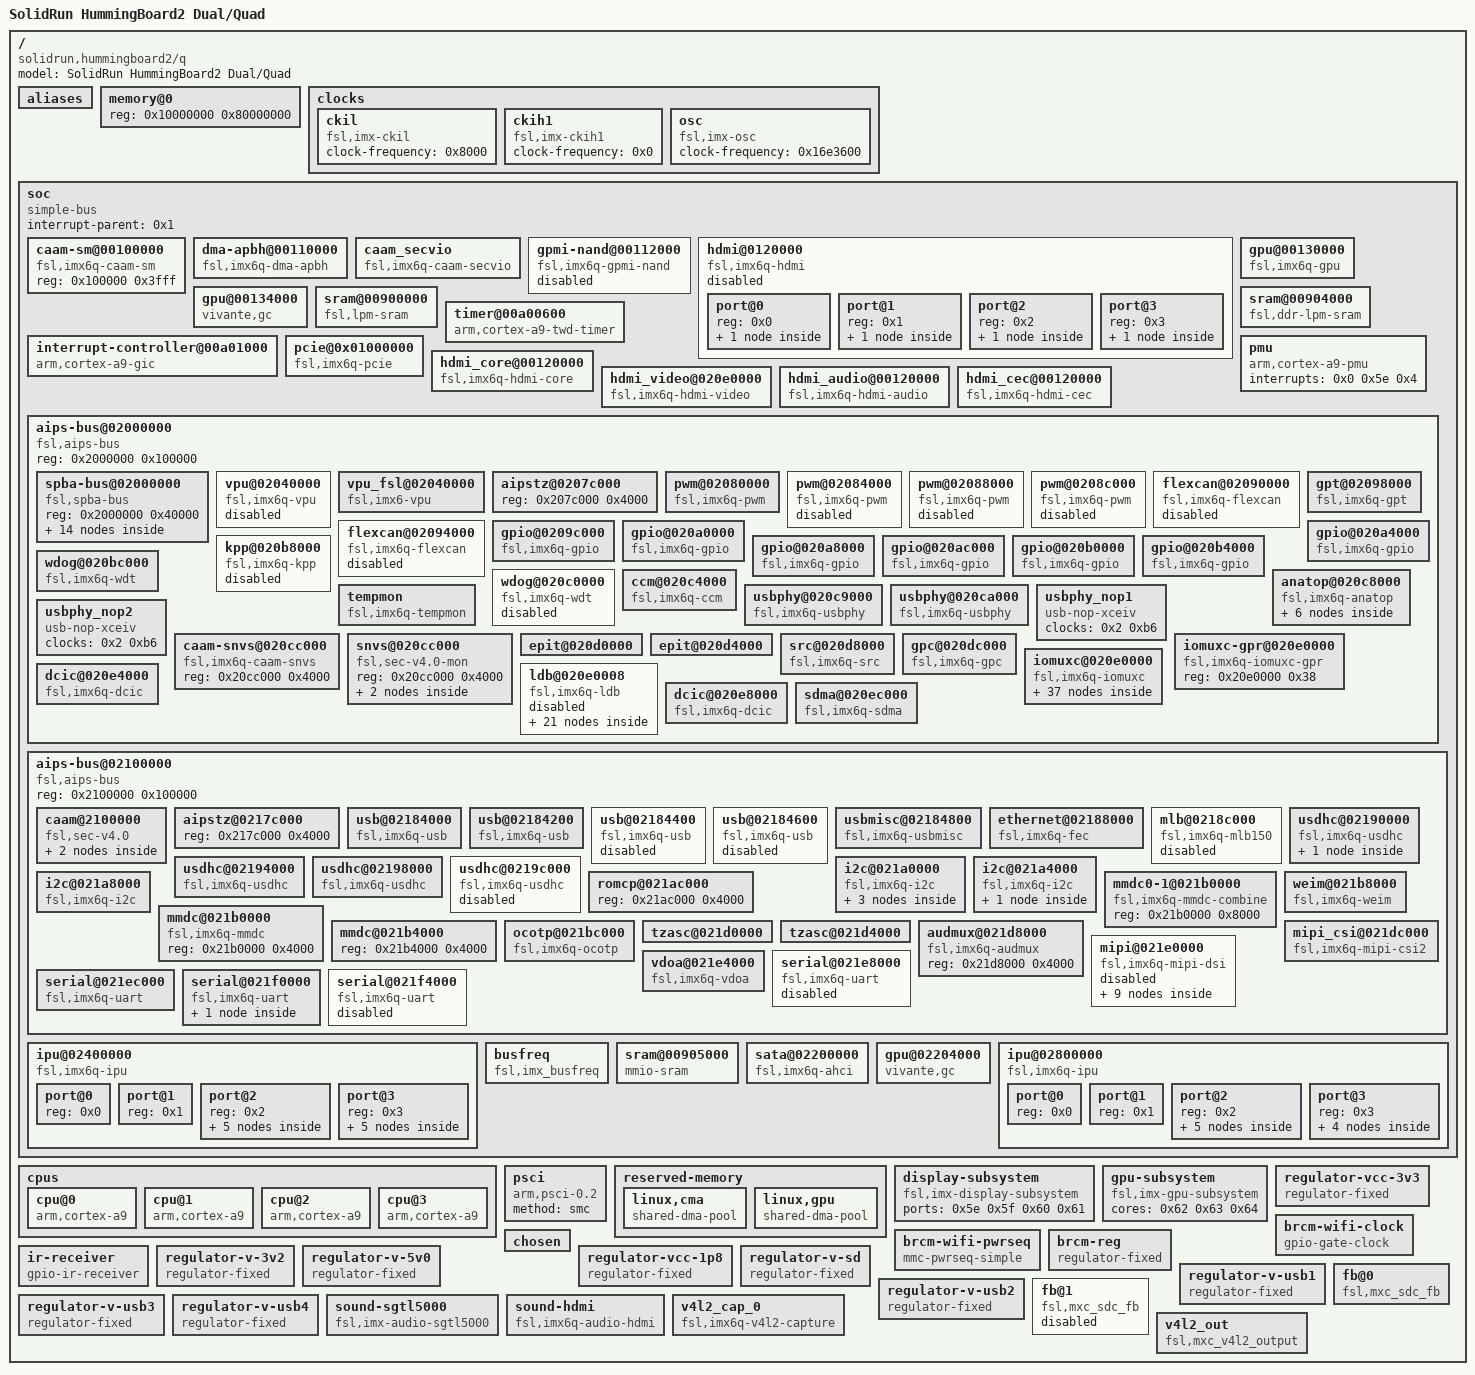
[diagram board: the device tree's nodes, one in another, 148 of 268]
/** @file
 * Copyright (c) 2017, Linaro Limited. All rights reserved.
 *
 * This program and the accompanying materials are licensed and made
 * available under the terms and conditions of the BSD License which
 * accompanies this distribution.  The full text of the license may be
 * found at http://opensource.org/licenses/bsd-license.php
 *
 * THE PROGRAM IS DISTRIBUTED UNDER THE BSD LICENSE ON AN "AS IS" BASIS,
 * WITHOUT WARRANTIES OR REPRESENTATIONS OF ANY KIND, EITHER EXPRESS OR
 * IMPLIED.
 */

/dts-v1/;

/ {
	#address-cells = <0x1>;
	#size-cells = <0x1>;
	model = "SolidRun HummingBoard2 Dual/Quad";
	compatible = "solidrun,hummingboard2/q", "fsl,imx6q";

	aliases {
		ethernet0 = "/soc/aips-bus@02100000/ethernet@02188000";
		can0 = "/soc/aips-bus@02000000/flexcan@02090000";
		can1 = "/soc/aips-bus@02000000/flexcan@02094000";
		gpio0 = "/soc/aips-bus@02000000/gpio@0209c000";
		gpio1 = "/soc/aips-bus@02000000/gpio@020a0000";
		gpio2 = "/soc/aips-bus@02000000/gpio@020a4000";
		gpio3 = "/soc/aips-bus@02000000/gpio@020a8000";
		gpio4 = "/soc/aips-bus@02000000/gpio@020ac000";
		gpio5 = "/soc/aips-bus@02000000/gpio@020b0000";
		gpio6 = "/soc/aips-bus@02000000/gpio@020b4000";
		i2c0 = "/soc/aips-bus@02100000/i2c@021a0000";
		i2c1 = "/soc/aips-bus@02100000/i2c@021a4000";
		i2c2 = "/soc/aips-bus@02100000/i2c@021a8000";
		ipu0 = "/soc/ipu@02400000";
		mmc0 = "/soc/aips-bus@02100000/usdhc@02194000";
		mmc1 = "/soc/aips-bus@02100000/usdhc@02190000";
		mmc2 = "/soc/aips-bus@02100000/usdhc@02198000";
		mmc3 = "/soc/aips-bus@02100000/usdhc@0219c000";
		serial0 = "/soc/aips-bus@02000000/spba-bus@02000000/serial@02020000";
		serial1 = "/soc/aips-bus@02100000/serial@021e8000";
		serial2 = "/soc/aips-bus@02100000/serial@021ec000";
		serial3 = "/soc/aips-bus@02100000/serial@021f0000";
		serial4 = "/soc/aips-bus@02100000/serial@021f4000";
		spi0 = "/soc/aips-bus@02000000/spba-bus@02000000/ecspi@02008000";
		spi1 = "/soc/aips-bus@02000000/spba-bus@02000000/ecspi@0200c000";
		spi2 = "/soc/aips-bus@02000000/spba-bus@02000000/ecspi@02010000";
		spi3 = "/soc/aips-bus@02000000/spba-bus@02000000/ecspi@02014000";
		usbphy0 = "/soc/aips-bus@02000000/usbphy@020c9000";
		usbphy1 = "/soc/aips-bus@02000000/usbphy@020ca000";
		ipu1 = "/soc/ipu@02800000";
		spi4 = "/soc/aips-bus@02000000/spba-bus@02000000/ecspi@02018000";
		mxcfb0 = "/fb@0";
		mxcfb2 = "/fb@1";
	};

	memory@0 {
		device_type = "memory";
		reg = <0x10000000 0x80000000>;
	};

	clocks {
		#address-cells = <0x1>;
		#size-cells = <0x0>;

		ckil {
			compatible = "fsl,imx-ckil", "fixed-clock";
			#clock-cells = <0x0>;
			clock-frequency = <0x8000>;
		};

		ckih1 {
			compatible = "fsl,imx-ckih1", "fixed-clock";
			#clock-cells = <0x0>;
			clock-frequency = <0x0>;
		};

		osc {
			compatible = "fsl,imx-osc", "fixed-clock";
			#clock-cells = <0x0>;
			clock-frequency = <0x16e3600>;
		};
	};

	soc {
		#address-cells = <0x1>;
		#size-cells = <0x1>;
		compatible = "simple-bus";
		interrupt-parent = <0x1>;
		ranges;

		caam-sm@00100000 {
			compatible = "fsl,imx6q-caam-sm";
			reg = <0x100000 0x3fff>;
		};

		dma-apbh@00110000 {
			compatible = "fsl,imx6q-dma-apbh", "fsl,imx28-dma-apbh";
			reg = <0x110000 0x2000>;
			interrupts = <0x0 0xd 0x4 0x0 0xd 0x4 0x0 0xd 0x4 0x0 0xd 0x4>;
			interrupt-names = "gpmi0", "gpmi1", "gpmi2", "gpmi3";
			#dma-cells = <0x1>;
			dma-channels = <0x4>;
			clocks = <0x2 0x6a>;
			linux,phandle = <0x3>;
			phandle = <0x3>;
		};

		caam_secvio {
			compatible = "fsl,imx6q-caam-secvio";
			interrupts = <0x0 0x14 0x4>;
			secvio_src = <0x8000001d>;
			jtag-tamper = "disabled";
			watchdog-tamper = "enabled";
			internal-boot-tamper = "enabled";
			external-pin-tamper = "disabled";
		};

		gpmi-nand@00112000 {
			compatible = "fsl,imx6q-gpmi-nand";
			#address-cells = <0x1>;
			#size-cells = <0x1>;
			reg = <0x112000 0x2000 0x114000 0x2000>;
			reg-names = "gpmi-nand", "bch";
			interrupts = <0x0 0xf 0x4>;
			interrupt-names = "bch";
			clocks = <0x2 0x98 0x2 0x99 0x2 0x97 0x2 0x96 0x2 0x95>;
			clock-names = "gpmi_io", "gpmi_apb", "gpmi_bch", "gpmi_bch_apb", "per1_bch";
			dmas = <0x3 0x0>;
			dma-names = "rx-tx";
			status = "disabled";
		};

		hdmi@0120000 {
			#address-cells = <0x1>;
			#size-cells = <0x0>;
			reg = <0x120000 0x9000>;
			interrupts = <0x0 0x73 0x4>;
			gpr = <0x4>;
			clocks = <0x2 0x7b 0x2 0x7c>;
			clock-names = "iahb", "isfr";
			status = "disabled";
			compatible = "fsl,imx6q-hdmi";
			pinctrl-names = "default";
			pinctrl-0 = <0x5>;
			ddc-i2c-bus = <0x6>;

			port@0 {
				reg = <0x0>;

				endpoint {
					remote-endpoint = <0x7>;
					linux,phandle = <0x4b>;
					phandle = <0x4b>;
				};
			};

			port@1 {
				reg = <0x1>;

				endpoint {
					remote-endpoint = <0x8>;
					linux,phandle = <0x4f>;
					phandle = <0x4f>;
				};
			};

			port@2 {
				reg = <0x2>;

				endpoint {
					remote-endpoint = <0x9>;
					linux,phandle = <0x53>;
					phandle = <0x53>;
				};
			};

			port@3 {
				reg = <0x3>;

				endpoint {
					remote-endpoint = <0xa>;
					linux,phandle = <0x57>;
					phandle = <0x57>;
				};
			};
		};

		gpu@00130000 {
			compatible = "fsl,imx6q-gpu";
			reg = <0x130000 0x4000 0x134000 0x4000 0x2204000 0x4000 0x10000000 0x0 0x0 0x8000000>;
			interrupts = <0x0 0x9 0x4 0x0 0xa 0x4 0x0 0xb 0x4>;
			clocks = <0x2 0x1a 0x2 0x8f 0x2 0x1b 0x2 0x79 0x2 0x7a 0x2 0x4a>;
			clock-names = "gpu2d_axi_clk", "openvg_axi_clk", "gpu3d_axi_clk", "gpu2d_clk", "gpu3d_clk", "gpu3d_shader_clk";
			power-domains = <0x1 0x1>;
			reg-names = "iobase_3d", "iobase_2d", "iobase_vg", "phys_baseaddr", "contiguous_mem";
			interrupt-names = "irq_3d", "irq_2d", "irq_vg";
			resets = <0xb 0x0 0xb 0x3 0xb 0x3>;
			reset-names = "gpu3d", "gpu2d", "gpuvg";
			memory-region = <0xc>;
			linux,phandle = <0x63>;
			phandle = <0x63>;
		};

		gpu@00134000 {
			compatible = "vivante,gc";
			reg = <0x134000 0x4000>;
			interrupts = <0x0 0xa 0x4>;
			clocks = <0x2 0x1a 0x2 0x79>;
			clock-names = "bus", "core";
			power-domains = <0x1 0x1>;
			memory-region = <0xc>;
			linux,phandle = <0x62>;
			phandle = <0x62>;
		};

		sram@00900000 {
			compatible = "fsl,lpm-sram";
			reg = <0x900000 0x4000>;
			clocks = <0x2 0x8e>;
		};

		sram@00904000 {
			compatible = "fsl,ddr-lpm-sram";
			reg = <0x904000 0x1000>;
			clocks = <0x2 0x8e>;
		};

		timer@00a00600 {
			compatible = "arm,cortex-a9-twd-timer";
			reg = <0xa00600 0x20>;
			interrupts = <0x1 0xd 0xf01>;
			interrupt-parent = <0xd>;
			clocks = <0x2 0xf>;
		};

		interrupt-controller@00a01000 {
			compatible = "arm,cortex-a9-gic";
			#interrupt-cells = <0x3>;
			interrupt-controller;
			reg = <0xa01000 0x1000 0xa00100 0x100>;
			interrupt-parent = <0xd>;
			linux,phandle = <0xd>;
			phandle = <0xd>;
		};

		pcie@0x01000000 {
			compatible = "fsl,imx6q-pcie", "snps,dw-pcie";
			reg = <0x1ffc000 0x4000 0x1f00000 0x80000>;
			reg-names = "dbi", "config";
			#address-cells = <0x3>;
			#size-cells = <0x2>;
			device_type = "pci";
			ranges = <0x81000000 0x0 0x0 0x1f80000 0x0 0x10000 0x82000000 0x0 0x1000000 0x1000000 0x0 0xf00000>;
			num-lanes = <0x1>;
			interrupts = <0x0 0x78 0x4>;
			interrupt-names = "msi";
			#interrupt-cells = <0x1>;
			interrupt-map-mask = <0x0 0x0 0x0 0x7>;
			interrupt-map = <0x0 0x0 0x0 0x1 0x1 0x0 0x7b 0x4 0x0 0x0 0x0 0x2 0x1 0x0 0x7a 0x4 0x0 0x0 0x0 0x3 0x1 0x0 0x79 0x4 0x0 0x0 0x0 0x4 0x1 0x0 0x78 0x4>;
			clocks = <0x2 0x90 0x2 0xce 0x2 0xbd>;
			clock-names = "pcie", "pcie_bus", "pcie_phy";
			fsl,max-link-speed = <0x2>;
			status = "okay";
			pinctrl-names = "default";
			pinctrl-0 = <0xe>;
			reset-gpio = <0xf 0xb 0x1>;
		};

		pmu {
			compatible = "arm,cortex-a9-pmu";
			interrupts = <0x0 0x5e 0x4>;
		};

		hdmi_core@00120000 {
			compatible = "fsl,imx6q-hdmi-core";
			reg = <0x120000 0x9000>;
			clocks = <0x2 0x7c 0x2 0x7b 0x2 0x8a>;
			clock-names = "hdmi_isfr", "hdmi_iahb", "mipi_core";
			status = "okay";
			ipu_id = <0x0>;
			disp_id = <0x0>;
		};

		hdmi_video@020e0000 {
			compatible = "fsl,imx6q-hdmi-video";
			reg = <0x20e0000 0x1000>;
			reg-names = "hdmi_gpr";
			interrupts = <0x0 0x73 0x4>;
			clocks = <0x2 0x7c 0x2 0x7b 0x2 0x8a>;
			clock-names = "hdmi_isfr", "hdmi_iahb", "mipi_core";
			status = "okay";
			fsl,phy_reg_vlev = <0x294>;
			fsl,phy_reg_cksymtx = <0x800d>;
		};

		hdmi_audio@00120000 {
			compatible = "fsl,imx6q-hdmi-audio";
			clocks = <0x2 0x7c 0x2 0x7b 0x2 0x8a>;
			clock-names = "hdmi_isfr", "hdmi_iahb", "mipi_core";
			dmas = <0x10 0x2 0x19 0x0>;
			dma-names = "tx";
			status = "okay";
			linux,phandle = <0x75>;
			phandle = <0x75>;
		};

		hdmi_cec@00120000 {
			compatible = "fsl,imx6q-hdmi-cec";
			interrupts = <0x0 0x73 0x4>;
			status = "okay";
			pinctrl-names = "default";
			pinctrl-0 = <0x5>;
		};

		aips-bus@02000000 {
			compatible = "fsl,aips-bus", "simple-bus";
			#address-cells = <0x1>;
			#size-cells = <0x1>;
			reg = <0x2000000 0x100000>;
			ranges;

			spba-bus@02000000 {
				compatible = "fsl,spba-bus", "simple-bus";
				#address-cells = <0x1>;
				#size-cells = <0x1>;
				reg = <0x2000000 0x40000>;
				ranges;

				spdif@02004000 {
					compatible = "fsl,imx35-spdif";
					reg = <0x2004000 0x4000>;
					interrupts = <0x0 0x34 0x4>;
					dmas = <0x10 0xe 0x12 0x0 0x10 0xf 0x12 0x0>;
					dma-names = "rx", "tx";
					clocks = <0x2 0xf4 0x2 0x3 0x2 0xc5 0x2 0x0 0x2 0x0 0x2 0x0 0x2 0x3e 0x2 0x0 0x2 0x0 0x2 0x9c>;
					clock-names = "core", "rxtx0", "rxtx1", "rxtx2", "rxtx3", "rxtx4", "rxtx5", "rxtx6", "rxtx7", "spba";
					status = "disabled";
				};

				ecspi@02008000 {
					#address-cells = <0x1>;
					#size-cells = <0x0>;
					compatible = "fsl,imx6q-ecspi", "fsl,imx51-ecspi";
					reg = <0x2008000 0x4000>;
					interrupts = <0x0 0x1f 0x4>;
					clocks = <0x2 0x70 0x2 0x70>;
					clock-names = "ipg", "per";
					dmas = <0x10 0x3 0x7 0x1 0x10 0x4 0x7 0x2>;
					dma-names = "rx", "tx";
					status = "disabled";
				};

				ecspi@0200c000 {
					#address-cells = <0x1>;
					#size-cells = <0x0>;
					compatible = "fsl,imx6q-ecspi", "fsl,imx51-ecspi";
					reg = <0x200c000 0x4000>;
					interrupts = <0x0 0x20 0x4>;
					clocks = <0x2 0x71 0x2 0x71>;
					clock-names = "ipg", "per";
					dmas = <0x10 0x5 0x7 0x1 0x10 0x6 0x7 0x2>;
					dma-names = "rx", "tx";
					status = "okay";
					pinctrl-names = "default";
					pinctrl-0 = <0x11>;
					cs-gpios = <0xf 0x1a 0x0>;
					fsl,spi-num-chipselects = <0x1>;

					spi@0 {
						compatible = "spidev";
						reg = <0x0>;
						spi-max-frequency = <0x1312d00>;
					};
				};

				ecspi@02010000 {
					#address-cells = <0x1>;
					#size-cells = <0x0>;
					compatible = "fsl,imx6q-ecspi", "fsl,imx51-ecspi";
					reg = <0x2010000 0x4000>;
					interrupts = <0x0 0x21 0x4>;
					clocks = <0x2 0x72 0x2 0x72>;
					clock-names = "ipg", "per";
					dmas = <0x10 0x7 0x7 0x1 0x10 0x8 0x7 0x2>;
					dma-names = "rx", "tx";
					status = "disabled";
				};

				ecspi@02014000 {
					#address-cells = <0x1>;
					#size-cells = <0x0>;
					compatible = "fsl,imx6q-ecspi", "fsl,imx51-ecspi";
					reg = <0x2014000 0x4000>;
					interrupts = <0x0 0x22 0x4>;
					clocks = <0x2 0x73 0x2 0x73>;
					clock-names = "ipg", "per";
					dmas = <0x10 0x9 0x7 0x1 0x10 0xa 0x7 0x2>;
					dma-names = "rx", "tx";
					status = "disabled";
				};

				serial@02020000 {
					compatible = "fsl,imx6q-uart", "fsl,imx21-uart";
					reg = <0x2020000 0x4000>;
					interrupts = <0x0 0x1a 0x4>;
					clocks = <0x2 0xa0 0x2 0xa1>;
					clock-names = "ipg", "per";
					dmas = <0x10 0x19 0x4 0x0 0x10 0x1a 0x4 0x0>;
					dma-names = "rx", "tx";
					status = "okay";
					pinctrl-names = "default";
					pinctrl-0 = <0x12>;
				};

				esai@02024000 {
					#sound-dai-cells = <0x0>;
					compatible = "fsl,imx35-esai";
					reg = <0x2024000 0x4000>;
					interrupts = <0x0 0x33 0x4>;
					clocks = <0x2 0xd0 0x2 0xd1 0x2 0x76 0x2 0xd0 0x2 0x9c>;
					clock-names = "core", "mem", "extal", "fsys", "spba";
					dmas = <0x10 0x17 0x15 0x0 0x10 0x18 0x15 0x0>;
					dma-names = "rx", "tx";
					status = "disabled";
				};

				ssi@02028000 {
					#sound-dai-cells = <0x0>;
					compatible = "fsl,imx6q-ssi", "fsl,imx51-ssi";
					reg = <0x2028000 0x4000>;
					interrupts = <0x0 0x2e 0x4>;
					clocks = <0x2 0xb2 0x2 0x9d>;
					clock-names = "ipg", "baud";
					dmas = <0x10 0x25 0x16 0x0 0x10 0x26 0x16 0x0>;
					dma-names = "rx", "tx";
					fsl,fifo-depth = <0xf>;
					status = "okay";
					fsl,mode = "i2s-slave";
					linux,phandle = <0x74>;
					phandle = <0x74>;
				};

				ssi@0202c000 {
					#sound-dai-cells = <0x0>;
					compatible = "fsl,imx6q-ssi", "fsl,imx51-ssi";
					reg = <0x202c000 0x4000>;
					interrupts = <0x0 0x2f 0x4>;
					clocks = <0x2 0xb3 0x2 0x9e>;
					clock-names = "ipg", "baud";
					dmas = <0x10 0x29 0x16 0x0 0x10 0x2a 0x16 0x0>;
					dma-names = "rx", "tx";
					fsl,fifo-depth = <0xf>;
					status = "disabled";
				};

				ssi@02030000 {
					#sound-dai-cells = <0x0>;
					compatible = "fsl,imx6q-ssi", "fsl,imx51-ssi";
					reg = <0x2030000 0x4000>;
					interrupts = <0x0 0x30 0x4>;
					clocks = <0x2 0xb4 0x2 0x9f>;
					clock-names = "ipg", "baud";
					dmas = <0x10 0x2d 0x16 0x0 0x10 0x2e 0x16 0x0>;
					dma-names = "rx", "tx";
					fsl,fifo-depth = <0xf>;
					status = "disabled";
				};

				asrc@02034000 {
					compatible = "fsl,imx53-asrc";
					reg = <0x2034000 0x4000>;
					interrupts = <0x0 0x32 0x4>;
					clocks = <0x2 0xd2 0x2 0xd3 0x2 0x0 0x2 0x0 0x2 0x0 0x2 0x0 0x2 0x0 0x2 0x0 0x2 0x0 0x2 0x0 0x2 0x0 0x2 0x0 0x2 0x0 0x2 0x0 0x2 0x0 0x2 0x6b 0x2 0x0 0x2 0x0 0x2 0x9c>;
					clock-names = "mem", "ipg", "asrck_0", "asrck_1", "asrck_2", "asrck_3", "asrck_4", "asrck_5", "asrck_6", "asrck_7", "asrck_8", "asrck_9", "asrck_a", "asrck_b", "asrck_c", "asrck_d", "asrck_e", "asrck_f", "spba";
					dmas = <0x10 0x11 0x17 0x1 0x10 0x12 0x17 0x1 0x10 0x13 0x17 0x1 0x10 0x14 0x17 0x1 0x10 0x15 0x17 0x1 0x10 0x16 0x17 0x1>;
					dma-names = "rxa", "rxb", "rxc", "txa", "txb", "txc";
					fsl,asrc-rate = <0xbb80>;
					fsl,asrc-width = <0x10>;
					status = "disabled";
				};

				spba@0203c000 {
					reg = <0x203c000 0x4000>;
				};

				ecspi@02018000 {
					#address-cells = <0x1>;
					#size-cells = <0x0>;
					compatible = "fsl,imx6q-ecspi", "fsl,imx51-ecspi";
					reg = <0x2018000 0x4000>;
					interrupts = <0x0 0x23 0x4>;
					clocks = <0x2 0x74 0x2 0x74>;
					clock-names = "ipg", "per";
					dmas = <0x10 0xb 0x8 0x1 0x10 0xc 0x8 0x2>;
					dma-names = "rx", "tx";
					status = "disabled";
				};
			};

			vpu@02040000 {
				compatible = "fsl,imx6q-vpu", "cnm,coda960";
				reg = <0x2040000 0x3c000>;
				interrupts = <0x0 0xc 0x4 0x0 0x3 0x4>;
				interrupt-names = "bit", "jpeg";
				clocks = <0x2 0xa8 0x2 0x8c>;
				clock-names = "per", "ahb";
				power-domains = <0x1 0x1>;
				resets = <0xb 0x1>;
				iram = <0x13>;
				status = "disabled";
			};

			vpu_fsl@02040000 {
				compatible = "fsl,imx6-vpu";
				reg = <0x2040000 0x3c000>;
				reg-names = "vpu_regs";
				interrupts = <0x0 0x3 0x1 0x0 0xc 0x4>;
				interrupt-names = "vpu_jpu_irq", "vpu_ipi_irq";
				clocks = <0x2 0xa8 0x2 0x8c 0x2 0x8e>;
				clock-names = "vpu_clk", "mmdc_ch0_axi", "ocram";
				iramsize = <0x21000>;
				iram = <0x13>;
				resets = <0xb 0x1>;
				power-domains = <0x1 0x1>;
				memory-region = <0xc>;
			};

			aipstz@0207c000 {
				reg = <0x207c000 0x4000>;
			};

			pwm@02080000 {
				#pwm-cells = <0x2>;
				compatible = "fsl,imx6q-pwm", "fsl,imx27-pwm";
				reg = <0x2080000 0x4000>;
				interrupts = <0x0 0x53 0x4>;
				clocks = <0x2 0x3e 0x2 0x91>;
				clock-names = "ipg", "per";
				status = "okay";
				pinctrl-names = "default";
				pinctrl-0 = <0x14>;
			};

			pwm@02084000 {
				#pwm-cells = <0x2>;
				compatible = "fsl,imx6q-pwm", "fsl,imx27-pwm";
				reg = <0x2084000 0x4000>;
				interrupts = <0x0 0x54 0x4>;
				clocks = <0x2 0x3e 0x2 0x92>;
				clock-names = "ipg", "per";
				status = "disabled";
			};

			pwm@02088000 {
				#pwm-cells = <0x2>;
				compatible = "fsl,imx6q-pwm", "fsl,imx27-pwm";
				reg = <0x2088000 0x4000>;
				interrupts = <0x0 0x55 0x4>;
				clocks = <0x2 0x3e 0x2 0x93>;
				clock-names = "ipg", "per";
				status = "disabled";
				pinctrl-names = "default";
				pinctrl-0 = <0x15>;
			};

			pwm@0208c000 {
				#pwm-cells = <0x2>;
				compatible = "fsl,imx6q-pwm", "fsl,imx27-pwm";
				reg = <0x208c000 0x4000>;
				interrupts = <0x0 0x56 0x4>;
				clocks = <0x2 0x3e 0x2 0x94>;
				clock-names = "ipg", "per";
				status = "disabled";
			};

			flexcan@02090000 {
				compatible = "fsl,imx6q-flexcan";
				reg = <0x2090000 0x4000>;
				interrupts = <0x0 0x6e 0x4>;
				clocks = <0x2 0x6c 0x2 0x6d>;
				clock-names = "ipg", "per";
				stop-mode = <0x4 0x34 0x1c 0x10 0x11>;
				status = "disabled";
				pinctrl-names = "default";
				pinctrl-0 = <0x16>;
			};

			flexcan@02094000 {
				compatible = "fsl,imx6q-flexcan";
				reg = <0x2094000 0x4000>;
				interrupts = <0x0 0x6f 0x4>;
				clocks = <0x2 0x6e 0x2 0x6f>;
				clock-names = "ipg", "per";
				stop-mode = <0x4 0x34 0x1d 0x10 0x12>;
				status = "disabled";
			};

			gpt@02098000 {
				compatible = "fsl,imx6q-gpt", "fsl,imx31-gpt";
				reg = <0x2098000 0x4000>;
				interrupts = <0x0 0x37 0x4>;
				clocks = <0x2 0x77 0x2 0x78 0x2 0xed>;
				clock-names = "ipg", "per", "osc_per";
			};

			gpio@0209c000 {
				compatible = "fsl,imx6q-gpio", "fsl,imx35-gpio";
				reg = <0x209c000 0x4000>;
				interrupts = <0x0 0x42 0x4 0x0 0x43 0x4>;
				gpio-controller;
				#gpio-cells = <0x2>;
				interrupt-controller;
				#interrupt-cells = <0x2>;
				gpio-ranges = <0x17 0x0 0x88 0x2 0x17 0x2 0x8d 0x1 0x17 0x3 0x8b 0x1 0x17 0x4 0x8e 0x2 0x17 0x6 0x8c 0x1 0x17 0x7 0x90 0x2 0x17 0x9 0x8a 0x1 0x17 0xa 0xd5 0x3 0x17 0xd 0x14 0x1 0x17 0xe 0x13 0x1 0x17 0xf 0x15 0x1 0x17 0x10 0xd0 0x1 0x17 0x11 0xcf 0x1 0x17 0x12 0xd2 0x3 0x17 0x15 0xd1 0x1 0x17 0x16 0x74 0xa>;
				linux,phandle = <0x39>;
				phandle = <0x39>;
			};

			gpio@020a0000 {
				compatible = "fsl,imx6q-gpio", "fsl,imx35-gpio";
				reg = <0x20a0000 0x4000>;
				interrupts = <0x0 0x44 0x4 0x0 0x45 0x4>;
				gpio-controller;
				#gpio-cells = <0x2>;
				interrupt-controller;
				#interrupt-cells = <0x2>;
				gpio-ranges = <0x17 0x0 0xbf 0x10 0x17 0x10 0x37 0xe 0x17 0x1e 0x23 0x1 0x17 0x1f 0x2c 0x1>;
				linux,phandle = <0xf>;
				phandle = <0xf>;
			};

			gpio@020a4000 {
				compatible = "fsl,imx6q-gpio", "fsl,imx35-gpio";
				reg = <0x20a4000 0x4000>;
				interrupts = <0x0 0x46 0x4 0x0 0x47 0x4>;
				gpio-controller;
				#gpio-cells = <0x2>;
				interrupt-controller;
				#interrupt-cells = <0x2>;
				gpio-ranges = <0x17 0x0 0x45 0x10 0x17 0x10 0x24 0x8 0x17 0x18 0x2d 0x8>;
				linux,phandle = <0x69>;
				phandle = <0x69>;
			};

			gpio@020a8000 {
				compatible = "fsl,imx6q-gpio", "fsl,imx35-gpio";
				reg = <0x20a8000 0x4000>;
				interrupts = <0x0 0x48 0x4 0x0 0x49 0x4>;
				gpio-controller;
				#gpio-cells = <0x2>;
				interrupt-controller;
				#interrupt-cells = <0x2>;
				gpio-ranges = <0x17 0x5 0x95 0x1 0x17 0x6 0x7e 0xa 0x17 0x10 0x57 0x10>;
				linux,phandle = <0x2f>;
				phandle = <0x2f>;
			};

			gpio@020ac000 {
				compatible = "fsl,imx6q-gpio", "fsl,imx35-gpio";
				reg = <0x20ac000 0x4000>;
				interrupts = <0x0 0x4a 0x4 0x0 0x4b 0x4>;
				gpio-controller;
				#gpio-cells = <0x2>;
				interrupt-controller;
				#interrupt-cells = <0x2>;
				gpio-ranges = <0x17 0x0 0x55 0x1 0x17 0x2 0x22 0x1 0x17 0x4 0x35 0x1 0x17 0x5 0x67 0xd 0x17 0x12 0x96 0xe>;
				linux,phandle = <0x66>;
				phandle = <0x66>;
			};

			gpio@020b0000 {
				compatible = "fsl,imx6q-gpio", "fsl,imx35-gpio";
				reg = <0x20b0000 0x4000>;
				interrupts = <0x0 0x4c 0x4 0x0 0x4d 0x4>;
				gpio-controller;
				#gpio-cells = <0x2>;
				interrupt-controller;
				#interrupt-cells = <0x2>;
				gpio-ranges = <0x17 0x0 0xa4 0x6 0x17 0x6 0x36 0x1 0x17 0x7 0xb5 0x5 0x17 0xe 0xba 0x3 0x17 0x11 0xaa 0x2 0x17 0x13 0x16 0xc 0x17 0x1f 0x56 0x1>;
				linux,phandle = <0x49>;
				phandle = <0x49>;
			};

			gpio@020b4000 {
				compatible = "fsl,imx6q-gpio", "fsl,imx35-gpio";
				reg = <0x20b4000 0x4000>;
				interrupts = <0x0 0x4e 0x4 0x0 0x4f 0x4>;
				gpio-controller;
				#gpio-cells = <0x2>;
				interrupt-controller;
				#interrupt-cells = <0x2>;
				gpio-ranges = <0x17 0x0 0xac 0x9 0x17 0x9 0xbd 0x2 0x17 0xb 0x92 0x3>;
				linux,phandle = <0x6b>;
				phandle = <0x6b>;
			};

			kpp@020b8000 {
				compatible = "fsl,imx6q-kpp", "fsl,imx21-kpp";
				reg = <0x20b8000 0x4000>;
				interrupts = <0x0 0x52 0x4>;
				clocks = <0x2 0x3e>;
				status = "disabled";
			};

			wdog@020bc000 {
				compatible = "fsl,imx6q-wdt", "fsl,imx21-wdt";
				reg = <0x20bc000 0x4000>;
				interrupts = <0x0 0x50 0x4>;
				clocks = <0x2 0x0>;
			};

			wdog@020c0000 {
				compatible = "fsl,imx6q-wdt", "fsl,imx21-wdt";
				reg = <0x20c0000 0x4000>;
				interrupts = <0x0 0x51 0x4>;
				clocks = <0x2 0x0>;
				status = "disabled";
			};

			ccm@020c4000 {
				compatible = "fsl,imx6q-ccm";
				reg = <0x20c4000 0x4000>;
				interrupts = <0x0 0x57 0x4 0x0 0x58 0x4>;
				#clock-cells = <0x1>;
				linux,phandle = <0x2>;
				phandle = <0x2>;
			};

			anatop@020c8000 {
				compatible = "fsl,imx6q-anatop", "syscon", "simple-bus";
				reg = <0x20c8000 0x1000>;
				interrupts = <0x0 0x31 0x4 0x0 0x36 0x4 0x0 0x7f 0x4>;
				linux,phandle = <0x18>;
				phandle = <0x18>;

				regulator-1p1 {
					compatible = "fsl,anatop-regulator";
					regulator-name = "vdd1p1";
					regulator-min-microvolt = <0xc3500>;
					regulator-max-microvolt = <0x14fb18>;
					regulator-always-on;
					anatop-reg-offset = <0x110>;
					anatop-vol-bit-shift = <0x8>;
					anatop-vol-bit-width = <0x5>;
					anatop-min-bit-val = <0x4>;
					anatop-min-voltage = <0xc3500>;
					anatop-max-voltage = <0x14fb18>;
					anatop-enable-bit = <0x0>;
				};

				regulator-3p0@120 {
					compatible = "fsl,anatop-regulator";
					regulator-name = "vdd3p0";
					regulator-min-microvolt = <0x280de8>;
					regulator-max-microvolt = <0x33e140>;
					anatop-reg-offset = <0x120>;
					anatop-vol-bit-shift = <0x8>;
					anatop-vol-bit-width = <0x5>;
					anatop-min-bit-val = <0x0>;
					anatop-min-voltage = <0x280de8>;
					anatop-max-voltage = <0x33e140>;
					anatop-enable-bit = <0x0>;
					linux,phandle = <0x1a>;
					phandle = <0x1a>;
				};

				regulator-2p5 {
					compatible = "fsl,anatop-regulator";
					regulator-name = "vdd2p5";
					regulator-min-microvolt = <0x1e8480>;
					regulator-max-microvolt = <0x29f630>;
					regulator-always-on;
					anatop-reg-offset = <0x130>;
					anatop-vol-bit-shift = <0x8>;
					anatop-vol-bit-width = <0x5>;
					anatop-min-bit-val = <0x0>;
					anatop-min-voltage = <0x1e8480>;
					anatop-max-voltage = <0x29f630>;
					anatop-enable-bit = <0x0>;
				};

				regulator-vddcore {
					compatible = "fsl,anatop-regulator";
					regulator-name = "vddarm";
					regulator-min-microvolt = <0xb1008>;
					regulator-max-microvolt = <0x162010>;
					regulator-always-on;
					anatop-reg-offset = <0x140>;
					anatop-vol-bit-shift = <0x0>;
					anatop-vol-bit-width = <0x5>;
					anatop-delay-reg-offset = <0x170>;
					anatop-delay-bit-shift = <0x18>;
					anatop-delay-bit-width = <0x2>;
					anatop-min-bit-val = <0x1>;
					anatop-min-voltage = <0xb1008>;
					anatop-max-voltage = <0x162010>;
					regulator-allow-bypass;
					linux,phandle = <0x5c>;
					phandle = <0x5c>;
				};

				regulator-vddpu {
					compatible = "fsl,anatop-regulator";
					regulator-name = "vddpu";
					regulator-min-microvolt = <0xb1008>;
					regulator-max-microvolt = <0x162010>;
					regulator-enable-ramp-delay = <0x96>;
					anatop-reg-offset = <0x140>;
					anatop-vol-bit-shift = <0x9>;
					anatop-vol-bit-width = <0x5>;
					anatop-delay-reg-offset = <0x170>;
					anatop-delay-bit-shift = <0x1a>;
					anatop-delay-bit-width = <0x2>;
					anatop-min-bit-val = <0x1>;
					anatop-min-voltage = <0xb1008>;
					anatop-max-voltage = <0x162010>;
					regulator-allow-bypass;
					linux,phandle = <0x1c>;
					phandle = <0x1c>;
				};

				regulator-vddsoc {
					compatible = "fsl,anatop-regulator";
					regulator-name = "vddsoc";
					regulator-min-microvolt = <0xb1008>;
					regulator-max-microvolt = <0x162010>;
					regulator-always-on;
					anatop-reg-offset = <0x140>;
					anatop-vol-bit-shift = <0x12>;
					anatop-vol-bit-width = <0x5>;
					anatop-delay-reg-offset = <0x170>;
					anatop-delay-bit-shift = <0x1c>;
					anatop-delay-bit-width = <0x2>;
					anatop-min-bit-val = <0x1>;
					anatop-min-voltage = <0xb1008>;
					anatop-max-voltage = <0x162010>;
					regulator-allow-bypass;
					linux,phandle = <0x5d>;
					phandle = <0x5d>;
				};
			};

			tempmon {
				compatible = "fsl,imx6q-tempmon";
				interrupts = <0x0 0x31 0x4>;
				fsl,tempmon = <0x18>;
				fsl,tempmon-data = <0x19>;
				clocks = <0x2 0xac>;
			};

			usbphy@020c9000 {
				compatible = "fsl,imx6q-usbphy", "fsl,imx23-usbphy";
				reg = <0x20c9000 0x1000>;
				interrupts = <0x0 0x2c 0x4>;
				clocks = <0x2 0xb6>;
				phy-3p0-supply = <0x1a>;
				fsl,anatop = <0x18>;
				linux,phandle = <0x27>;
				phandle = <0x27>;
			};

			usbphy@020ca000 {
				compatible = "fsl,imx6q-usbphy", "fsl,imx23-usbphy";
				reg = <0x20ca000 0x1000>;
				interrupts = <0x0 0x2d 0x4>;
				clocks = <0x2 0xb7>;
				phy-3p0-supply = <0x1a>;
				fsl,anatop = <0x18>;
				linux,phandle = <0x2b>;
				phandle = <0x2b>;
			};

			usbphy_nop1 {
				compatible = "usb-nop-xceiv";
				clocks = <0x2 0xb6>;
				clock-names = "main_clk";
				linux,phandle = <0x2c>;
				phandle = <0x2c>;
			};

			usbphy_nop2 {
				compatible = "usb-nop-xceiv";
				clocks = <0x2 0xb6>;
				clock-names = "main_clk";
				linux,phandle = <0x2d>;
				phandle = <0x2d>;
			};

			caam-snvs@020cc000 {
				compatible = "fsl,imx6q-caam-snvs";
				reg = <0x20cc000 0x4000>;
			};

			snvs@020cc000 {
				compatible = "fsl,sec-v4.0-mon", "syscon", "simple-mfd";
				reg = <0x20cc000 0x4000>;
				linux,phandle = <0x1b>;
				phandle = <0x1b>;

				snvs-rtc-lp {
					compatible = "fsl,sec-v4.0-mon-rtc-lp";
					regmap = <0x1b>;
					offset = <0x34>;
					interrupts = <0x0 0x13 0x4 0x0 0x14 0x4>;
				};

				snvs-poweroff {
					compatible = "syscon-poweroff";
					regmap = <0x1b>;
					offset = <0x38>;
					mask = <0x61>;
					status = "disabled";
				};
			};

			epit@020d0000 {
				reg = <0x20d0000 0x4000>;
				interrupts = <0x0 0x38 0x4>;
			};

			epit@020d4000 {
				reg = <0x20d4000 0x4000>;
				interrupts = <0x0 0x39 0x4>;
			};

			src@020d8000 {
				compatible = "fsl,imx6q-src", "fsl,imx51-src";
				reg = <0x20d8000 0x4000>;
				interrupts = <0x0 0x5b 0x4 0x0 0x60 0x4>;
				#reset-cells = <0x1>;
				linux,phandle = <0xb>;
				phandle = <0xb>;
			};

			gpc@020dc000 {
				compatible = "fsl,imx6q-gpc";
				reg = <0x20dc000 0x4000>;
				interrupt-controller;
				#interrupt-cells = <0x3>;
				interrupts = <0x0 0x59 0x4 0x0 0x5a 0x4>;
				interrupt-parent = <0xd>;
				pu-supply = <0x1c>;
				clocks = <0x2 0x7a 0x2 0x4a 0x2 0x79 0x2 0x1a 0x2 0x8f 0x2 0xa8 0x2 0x3e>;
				#power-domain-cells = <0x1>;
				fsl,cpu_pupscr_sw2iso = <0xf>;
				fsl,cpu_pupscr_sw = <0xf>;
				fsl,cpu_pdnscr_iso2sw = <0x1>;
				fsl,cpu_pdnscr_iso = <0x1>;
				linux,phandle = <0x1>;
				phandle = <0x1>;
			};

			iomuxc-gpr@020e0000 {
				compatible = "fsl,imx6q-iomuxc-gpr", "syscon";
				reg = <0x20e0000 0x38>;
				linux,phandle = <0x4>;
				phandle = <0x4>;
			};

			iomuxc@020e0000 {
				compatible = "fsl,imx6q-iomuxc";
				reg = <0x20e0000 0x4000>;
				pinctrl-names = "default";
				pinctrl-0 = <0x1d>;
				linux,phandle = <0x17>;
				phandle = <0x17>;

				microsom {

					microsom-enet-ar8035 {
						fsl,pins = <0x1d0 0x4e4 0x840 0x1 0x0 0x1b8b0 0x1f4 0x508 0x0 0x1 0x0 0x1b0b0 0x21c 0x5ec 0x0 0x5 0x0 0x130b0 0x164 0x478 0x0 0x5 0x0 0x1b0b0 0x248 0x618 0x83c 0x2 0x1 0x4001b0b0 0x58 0x36c 0x0 0x1 0x0 0x13030 0x5c 0x370 0x0 0x1 0x0 0x1b030 0x60 0x374 0x0 0x1 0x0 0x1b030 0x64 0x378 0x0 0x1 0x0 0x1b030 0x68 0x37c 0x0 0x1 0x0 0x1b030 0x74 0x388 0x0 0x1 0x0 0x1b030 0x1d4 0x4e8 0x0 0x1 0x0 0xa0b1 0x84 0x398 0x844 0x1 0x0 0x1b030 0x70 0x384 0x848 0x1 0x0 0x13030 0x78 0x38c 0x84c 0x1 0x0 0x13030 0x7c 0x390 0x850 0x1 0x0 0x1b030 0x80 0x394 0x854 0x1 0x0 0x1b030 0x6c 0x380 0x858 0x1 0x0 0x13030 0x1dc 0x4f0 0x0 0x5 0x0 0x3000 0x1e4 0x4f8 0x0 0x5 0x0 0x3000 0x1e0 0x4f4 0x0 0x5 0x0 0x3000>;
						linux,phandle = <0x2e>;
						phandle = <0x2e>;
					};

					microsom-uart1 {
						fsl,pins = <0x280 0x650 0x0 0x3 0x0 0x1b0b1 0x284 0x654 0x920 0x3 0x1 0x1b0b1>;
						linux,phandle = <0x12>;
						phandle = <0x12>;
					};

					microsom-brcm-bt {
						fsl,pins = <0x294 0x664 0x0 0x5 0x0 0x40013070 0x2a0 0x670 0x0 0x5 0x0 0x40013070 0x2a4 0x674 0x0 0x5 0x0 0x40013070>;
						linux,phandle = <0x4a>;
						phandle = <0x4a>;
					};

					microsom-brcm-bt-en {
						fsl,pins = <0x290 0x660 0x0 0x5 0x0 0x40013070>;
						linux,phandle = <0x68>;
						phandle = <0x68>;
					};

					microsom-brcm-reg {
						fsl,pins = <0x9c 0x3b0 0x0 0x5 0x0 0x40013070>;
						linux,phandle = <0x6a>;
						phandle = <0x6a>;
					};

					microsom-brcm-clk {
						fsl,pins = <0x244 0x614 0x0 0x1 0x0 0xb0 0x19c 0x4b0 0x0 0x5 0x0 0x40013070>;
						linux,phandle = <0x65>;
						phandle = <0x65>;
					};

					microsom-brcm-wifi-en {
						fsl,pins = <0x278 0x648 0x0 0x5 0x0 0x40013070>;
						linux,phandle = <0x67>;
						phandle = <0x67>;
					};

					microsom-brcm-wifi-irq {
						fsl,pins = <0x27c 0x64c 0x0 0x5 0x0 0x1b0b0 0x260 0x630 0x0 0x5 0x0 0x1b0b0>;
						linux,phandle = <0x33>;
						phandle = <0x33>;
					};

					microsom-uart4 {
						fsl,pins = <0x288 0x658 0x0 0x3 0x0 0x1b0b1 0x28c 0x65c 0x938 0x3 0x3 0x1b0b1 0x298 0x668 0x934 0x3 0x0 0x1b0b1 0x29c 0x66c 0x0 0x3 0x0 0x1b0b1>;
						linux,phandle = <0x47>;
						phandle = <0x47>;
					};

					microsom-usdhc1 {
						fsl,pins = <0x348 0x730 0x0 0x0 0x0 0x17059 0x350 0x738 0x0 0x0 0x0 0x10059 0x340 0x728 0x0 0x0 0x0 0x17059 0x33c 0x724 0x0 0x0 0x0 0x17059 0x34c 0x734 0x0 0x0 0x0 0x17059 0x344 0x72c 0x0 0x0 0x0 0x17059>;
						linux,phandle = <0x30>;
						phandle = <0x30>;
					};
				};

				hummingboard2 {

					hoggrp {
						fsl,pins = <0x13c 0x450 0x0 0x5 0x0 0x400130b1 0x140 0x454 0x0 0x5 0x0 0x400130b1 0x138 0x44c 0x0 0x5 0x0 0x400130b1 0x134 0x448 0x0 0x5 0x0 0x400130b1 0x130 0x444 0x0 0x5 0x0 0x400130b1 0x12c 0x440 0x0 0x5 0x0 0x400130b1 0x128 0x43c 0x0 0x5 0x0 0x400130b1 0x124 0x438 0x0 0x5 0x0 0x400130b1 0x120 0x434 0x0 0x5 0x0 0x400130b1 0x11c 0x430 0x0 0x5 0x0 0x400130b1 0x148 0x45c 0x0 0x5 0x0 0x400130b1 0x14c 0x460 0x0 0x5 0x0 0x400130b1 0x150 0x464 0x0 0x5 0x0 0x400130b1 0x144 0x458 0x0 0x5 0x0 0x400130b1 0x118 0x42c 0x0 0x5 0x0 0x400130b1 0x114 0x428 0x0 0x5 0x0 0x400130b1 0x110 0x424 0x0 0x5 0x0 0x400130b1 0x10c 0x420 0x0 0x5 0x0 0x400130b1 0xf0 0x404 0x0 0x5 0x0 0x400130b1 0xec 0x400 0x0 0x5 0x0 0x400130b1 0xe8 0x3fc 0x0 0x5 0x0 0x400130b1 0xe4 0x3f8 0x0 0x5 0x0 0x400130b1 0xe0 0x3f4 0x0 0x5 0x0 0x400130b1 0xdc 0x3f0 0x0 0x5 0x0 0x400130b1 0xd8 0x3ec 0x0 0x5 0x0 0x400130b1 0xd4 0x3e8 0x0 0x5 0x0 0x400130b1 0xd0 0x3e4 0x0 0x5 0x0 0x400130b1 0xcc 0x3e0 0x0 0x5 0x0 0x400130b1 0xbc 0x3d0 0x0 0x5 0x0 0x400130b1 0xc0 0x3d4 0x0 0x5 0x0 0x400130b1 0xf4 0x408 0x0 0x5 0x0 0x400130b1 0x1d8 0x4ec 0x0 0x5 0x0 0x400130b1 0x24c 0x61c 0x0 0x5 0x0 0x400130b1 0x108 0x41c 0x0 0x5 0x0 0x400130b1>;
						linux,phandle = <0x1d>;
						phandle = <0x1d>;
					};

					hummingboard2-ecspi2grp {
						fsl,pins = <0x100 0x414 0x814 0x2 0x0 0x100b1 0xfc 0x410 0x818 0x2 0x0 0x100b1 0xf8 0x40c 0x810 0x2 0x0 0x100b1 0x104 0x418 0x0 0x5 0x0 0xb1>;
						linux,phandle = <0x11>;
						phandle = <0x11>;
					};

					hummingboard2-gpio7_9 {
						fsl,pins = <0x2f4 0x6dc 0x0 0x5 0x0 0x80000000>;
						linux,phandle = <0x6c>;
						phandle = <0x6c>;
					};

					hummingboard2-hdmi {
						fsl,pins = <0x20c 0x5dc 0x88c 0x6 0x1 0x1f8b0>;
						linux,phandle = <0x5>;
						phandle = <0x5>;
					};

					hummingboard2-i2c1 {
						fsl,pins = <0xa4 0x3b8 0x898 0x6 0x0 0x4001b8b1 0xc4 0x3d8 0x89c 0x1 0x0 0x4001b8b1>;
						linux,phandle = <0x3c>;
						phandle = <0x3c>;
					};

					hummingboard2-i2c2 {
						fsl,pins = <0x210 0x5e0 0x8a0 0x4 0x1 0x4001b8b1 0x214 0x5e4 0x8a4 0x4 0x1 0x4001b8b1>;
						linux,phandle = <0x40>;
						phandle = <0x40>;
					};

					hummingboard2-i2c3 {
						fsl,pins = <0x94 0x3a8 0x8a8 0x6 0x0 0x4001b8b1 0x98 0x3ac 0x8ac 0x6 0x0 0x4001b8b1>;
						linux,phandle = <0x41>;
						phandle = <0x41>;
					};

					hummingboard2_mipi {
						fsl,pins = <0x324 0x70c 0x0 0x5 0x0 0x4001b8b1 0x218 0x5e8 0x0 0x5 0x0 0x4001b8b1 0x2ec 0x6d4 0x0 0x4 0x0 0x130b0>;
						linux,phandle = <0x3f>;
						phandle = <0x3f>;
					};

					hummingboard2-pcie-reset {
						fsl,pins = <0x328 0x710 0x0 0x5 0x0 0x1b0b1>;
						linux,phandle = <0xe>;
						phandle = <0xe>;
					};

					pwm1grp {
						fsl,pins = <0x190 0x4a4 0x0 0x2 0x0 0x1b0b1>;
						linux,phandle = <0x14>;
						phandle = <0x14>;
					};

					pwm3grp {
						fsl,pins = <0x320 0x708 0x0 0x2 0x0 0x1b0b1>;
						linux,phandle = <0x15>;
						phandle = <0x15>;
					};

					hummingboard2-sgtl5000 {
						fsl,pins = <0x1bc 0x4d0 0x7cc 0x3 0x0 0x130b0 0x1f8 0x5c8 0x7dc 0x2 0x1 0x130b0 0x1fc 0x5cc 0x7d0 0x2 0x1 0x110b0 0x200 0x5d0 0x7e0 0x2 0x1 0x130b0 0x23c 0x60c 0x0 0x3 0x0 0x130b0>;
						linux,phandle = <0x3d>;
						phandle = <0x3d>;
					};

					hummingboard2-usbh1-vbus {
						fsl,pins = <0x220 0x5f0 0x0 0x5 0x0 0x1b0b0>;
						linux,phandle = <0x70>;
						phandle = <0x70>;
					};

					hummingboard2-usbh2-vbus {
						fsl,pins = <0x330 0x718 0x0 0x5 0x0 0x1b0b0>;
						linux,phandle = <0x71>;
						phandle = <0x71>;
					};

					hummingboard2-usbh3-vbus {
						fsl,pins = <0x2f8 0x6e0 0x0 0x5 0x0 0x1b0b0>;
						linux,phandle = <0x72>;
						phandle = <0x72>;
					};

					hummingboard2-usbotg-id {
						fsl,pins = <0x224 0x5f4 0x4 0x3 0xff0d0101 0x13059>;
						linux,phandle = <0x29>;
						phandle = <0x29>;
					};

					hummingboard2-usbotg-vbus {
						fsl,pins = <0xa8 0x3bc 0x0 0x5 0x0 0x1b0b0>;
						linux,phandle = <0x6e>;
						phandle = <0x6e>;
					};

					hummingboard2-usdhc2-aux {
						fsl,pins = <0x238 0x608 0x0 0x5 0x0 0x1f071 0x204 0x5d4 0x0 0x6 0x0 0x1b071>;
						linux,phandle = <0x34>;
						phandle = <0x34>;
					};

					hummingboard2-usdhc2 {
						fsl,pins = <0x358 0x740 0x0 0x0 0x0 0x17059 0x354 0x73c 0x0 0x0 0x0 0x10059 0x54 0x368 0x0 0x0 0x0 0x17059 0x4c 0x360 0x0 0x0 0x0 0x17059 0x50 0x364 0x0 0x0 0x0 0x17059 0x35c 0x744 0x0 0x0 0x0 0x13059>;
						linux,phandle = <0x35>;
						phandle = <0x35>;
					};

					hummingboard2-usdhc2-100mhz {
						fsl,pins = <0x358 0x740 0x0 0x0 0x0 0x170b9 0x354 0x73c 0x0 0x0 0x0 0x100b9 0x54 0x368 0x0 0x0 0x0 0x170b9 0x4c 0x360 0x0 0x0 0x0 0x170b9 0x50 0x364 0x0 0x0 0x0 0x170b9 0x35c 0x744 0x0 0x0 0x0 0x130b9>;
						linux,phandle = <0x36>;
						phandle = <0x36>;
					};

					hummingboard2-usdhc2-200mhz {
						fsl,pins = <0x358 0x740 0x0 0x0 0x0 0x170f9 0x354 0x73c 0x0 0x0 0x0 0x100f9 0x54 0x368 0x0 0x0 0x0 0x170f9 0x4c 0x360 0x0 0x0 0x0 0x170f9 0x50 0x364 0x0 0x0 0x0 0x170f9 0x35c 0x744 0x0 0x0 0x0 0x130f9>;
						linux,phandle = <0x37>;
						phandle = <0x37>;
					};

					hummingboard2-vmmc {
						fsl,pins = <0x194 0x4a8 0x0 0x5 0x0 0x1b0b0>;
						linux,phandle = <0x6d>;
						phandle = <0x6d>;
					};

					hummingboard2-uart3 {
						fsl,pins = <0xb8 0x3cc 0x0 0x2 0x0 0x1b0b1 0xb4 0x3c8 0x930 0x2 0x0 0x40013000>;
						linux,phandle = <0x46>;
						phandle = <0x46>;
					};

					hummingboard2-usdhc3 {
						fsl,pins = <0x2b8 0x6a0 0x0 0x0 0x0 0x17059 0x2bc 0x6a4 0x0 0x0 0x0 0x10059 0x2c0 0x6a8 0x0 0x0 0x0 0x17059 0x2c4 0x6ac 0x0 0x0 0x0 0x17059 0x2c8 0x6b0 0x0 0x0 0x0 0x17059 0x2cc 0x6b4 0x0 0x0 0x0 0x17059 0x2b4 0x69c 0x0 0x0 0x0 0x17059 0x2b0 0x698 0x0 0x0 0x0 0x17059 0x2ac 0x694 0x0 0x0 0x0 0x17059 0x2a8 0x690 0x0 0x0 0x0 0x17059 0x2d0 0x6b8 0x0 0x0 0x0 0x17059>;
						linux,phandle = <0x3a>;
						phandle = <0x3a>;
					};

					hummingboard-flexcan1 {
						fsl,pins = <0x20c 0x5dc 0x7e4 0x2 0x0 0x1b0b1 0x208 0x5d8 0x0 0x2 0x0 0x1b0b1>;
						linux,phandle = <0x16>;
						phandle = <0x16>;
					};
				};
			};

			ldb@020e0008 {
				#address-cells = <0x1>;
				#size-cells = <0x0>;
				compatible = "fsl,imx6q-ldb", "fsl,imx53-ldb";
				gpr = <0x4>;
				status = "disabled";
				clocks = <0x2 0x87 0x2 0x88 0x2 0x27 0x2 0x28 0x2 0x29 0x2 0x2a 0x2 0xb8 0x2 0xb9 0x2 0x106 0x2 0x107 0x2 0x108 0x2 0x109 0x2 0x8d 0x2 0x4 0x2 0x6 0x2 0xac>;
				clock-names = "ldb_di0", "ldb_di1", "di0_sel", "di1_sel", "di2_sel", "di3_sel", "ldb_di0_div_3_5", "ldb_di1_div_3_5", "ldb_di0_div_7", "ldb_di1_div_7", "ldb_di0_div_sel", "ldb_di1_div_sel", "choice0", "choice1", "choice2", "choice3";

				lvds-channel@0 {
					#address-cells = <0x1>;
					#size-cells = <0x0>;
					reg = <0x0>;
					status = "disabled";

					port@0 {
						reg = <0x0>;

						endpoint {
							remote-endpoint = <0x1e>;
							linux,phandle = <0x4d>;
							phandle = <0x4d>;
						};
					};

					port@1 {
						reg = <0x1>;

						endpoint {
							remote-endpoint = <0x1f>;
							linux,phandle = <0x51>;
							phandle = <0x51>;
						};
					};

					port@2 {
						reg = <0x2>;

						endpoint {
							remote-endpoint = <0x20>;
							linux,phandle = <0x55>;
							phandle = <0x55>;
						};
					};

					port@3 {
						reg = <0x3>;

						endpoint {
							remote-endpoint = <0x21>;
							linux,phandle = <0x59>;
							phandle = <0x59>;
						};
					};
				};

				lvds-channel@1 {
					#address-cells = <0x1>;
					#size-cells = <0x0>;
					reg = <0x1>;
					status = "disabled";

					port@0 {
						reg = <0x0>;

						endpoint {
							remote-endpoint = <0x22>;
							linux,phandle = <0x4e>;
							phandle = <0x4e>;
						};
					};

					port@1 {
						reg = <0x1>;

						endpoint {
							remote-endpoint = <0x23>;
							linux,phandle = <0x52>;
							phandle = <0x52>;
						};
					};

					port@2 {
						reg = <0x2>;

						endpoint {
							remote-endpoint = <0x24>;
							linux,phandle = <0x56>;
							phandle = <0x56>;
						};
					};

					port@3 {
						reg = <0x3>;

						endpoint {
							remote-endpoint = <0x25>;
							linux,phandle = <0x5a>;
							phandle = <0x5a>;
						};
					};
				};

				lvds@0 {
					fsl,data-mapping = "spwg";
					fsl,data-width = <0x12>;
					crtc = "ipu2-di0";
					primary;

					display-timings {
						native-mode = <0x26>;

						hsd100pxn1 {
							clock-frequency = <0x3dfd240>;
							hactive = <0x400>;
							vactive = <0x300>;
							hback-porch = <0xdc>;
							hfront-porch = <0x28>;
							vback-porch = <0x15>;
							vfront-porch = <0x7>;
							hsync-len = <0x3c>;
							vsync-len = <0xa>;
							linux,phandle = <0x26>;
							phandle = <0x26>;
						};
					};
				};
			};

			dcic@020e4000 {
				compatible = "fsl,imx6q-dcic";
				reg = <0x20e4000 0x4000>;
				interrupts = <0x0 0x7c 0x4>;
				clocks = <0x2 0x10a 0x2 0x10a>;
				clock-names = "dcic", "disp-axi";
				gpr = <0x4>;
				status = "okay";
				dcic_id = <0x0>;
				dcic_mux = "dcic-hdmi";
			};

			dcic@020e8000 {
				compatible = "fsl,imx6q-dcic";
				reg = <0x20e8000 0x4000>;
				interrupts = <0x0 0x7d 0x4>;
				clocks = <0x2 0x10b 0x2 0x10b>;
				clock-names = "dcic", "disp-axi";
				gpr = <0x4>;
				status = "okay";
				dcic_id = <0x1>;
				dcic_mux = "dcic-lvds1";
			};

			sdma@020ec000 {
				compatible = "fsl,imx6q-sdma", "fsl,imx35-sdma";
				reg = <0x20ec000 0x4000>;
				interrupts = <0x0 0x2 0x4>;
				clocks = <0x2 0x9b 0x2 0x9b>;
				clock-names = "ipg", "ahb";
				#dma-cells = <0x3>;
				fsl,sdma-ram-script-name = "imx/sdma/sdma-imx6q.bin";
				linux,phandle = <0x10>;
				phandle = <0x10>;
			};
		};

		aips-bus@02100000 {
			compatible = "fsl,aips-bus", "simple-bus";
			#address-cells = <0x1>;
			#size-cells = <0x1>;
			reg = <0x2100000 0x100000>;
			ranges;

			caam@2100000 {
				compatible = "fsl,sec-v4.0";
				#address-cells = <0x1>;
				#size-cells = <0x1>;
				reg = <0x2100000 0x10000>;
				ranges = <0x0 0x2100000 0x40000>;
				interrupt-parent = <0xd>;
				clocks = <0x2 0xf1 0x2 0xf2 0x2 0xf3 0x2 0xc4>;
				clock-names = "mem", "aclk", "ipg", "emi_slow";

				jr0@1000 {
					compatible = "fsl,sec-v4.0-job-ring";
					reg = <0x1000 0x1000>;
					interrupts = <0x0 0x69 0x4>;
				};

				jr1@2000 {
					compatible = "fsl,sec-v4.0-job-ring";
					reg = <0x2000 0x1000>;
					interrupts = <0x0 0x6a 0x4>;
				};
			};

			aipstz@0217c000 {
				reg = <0x217c000 0x4000>;
			};

			usb@02184000 {
				compatible = "fsl,imx6q-usb", "fsl,imx27-usb";
				reg = <0x2184000 0x200>;
				interrupts = <0x0 0x2b 0x4>;
				clocks = <0x2 0xa2>;
				fsl,usbphy = <0x27>;
				fsl,usbmisc = <0x28 0x0>;
				ahb-burst-config = <0x0>;
				tx-burst-size-dword = <0x10>;
				rx-burst-size-dword = <0x10>;
				fsl,anatop = <0x18>;
				status = "okay";
				disable-over-current;
				pinctrl-names = "default";
				pinctrl-0 = <0x29>;
				vbus-supply = <0x2a>;
			};

			usb@02184200 {
				compatible = "fsl,imx6q-usb", "fsl,imx27-usb";
				reg = <0x2184200 0x200>;
				interrupts = <0x0 0x28 0x4>;
				clocks = <0x2 0xa2>;
				fsl,usbphy = <0x2b>;
				fsl,usbmisc = <0x28 0x1>;
				dr_mode = "host";
				ahb-burst-config = <0x0>;
				tx-burst-size-dword = <0x10>;
				rx-burst-size-dword = <0x10>;
				status = "okay";
				disable-over-current;
			};

			usb@02184400 {
				compatible = "fsl,imx6q-usb", "fsl,imx27-usb";
				reg = <0x2184400 0x200>;
				interrupts = <0x0 0x29 0x4>;
				clocks = <0x2 0xa2>;
				fsl,usbmisc = <0x28 0x2>;
				dr_mode = "host";
				ahb-burst-config = <0x0>;
				tx-burst-size-dword = <0x10>;
				rx-burst-size-dword = <0x10>;
				phy_type = "hsic";
				fsl,usbphy = <0x2c>;
				fsl,anatop = <0x18>;
				status = "disabled";
			};

			usb@02184600 {
				compatible = "fsl,imx6q-usb", "fsl,imx27-usb";
				reg = <0x2184600 0x200>;
				interrupts = <0x0 0x2a 0x4>;
				clocks = <0x2 0xa2>;
				fsl,usbmisc = <0x28 0x3>;
				dr_mode = "host";
				ahb-burst-config = <0x0>;
				tx-burst-size-dword = <0x10>;
				rx-burst-size-dword = <0x10>;
				phy_type = "hsic";
				fsl,usbphy = <0x2d>;
				fsl,anatop = <0x18>;
				status = "disabled";
			};

			usbmisc@02184800 {
				#index-cells = <0x1>;
				compatible = "fsl,imx6q-usbmisc";
				reg = <0x2184800 0x200>;
				clocks = <0x2 0xa2>;
				linux,phandle = <0x28>;
				phandle = <0x28>;
			};

			ethernet@02188000 {
				compatible = "fsl,imx6q-fec";
				reg = <0x2188000 0x4000>;
				interrupts-extended = <0x1 0x0 0x76 0x4 0x1 0x0 0x77 0x4>;
				clocks = <0x2 0x75 0x2 0x75 0x2 0xbe>;
				clock-names = "ipg", "ahb", "ptp";
				stop-mode = <0x4 0x34 0x1b>;
				fsl,wakeup_irq = <0x0>;
				status = "okay";
				pinctrl-names = "default";
				pinctrl-0 = <0x2e>;
				phy-mode = "rgmii";
				phy-reset-duration = <0x2>;
				phy-reset-gpios = <0x2f 0xf 0x1>;
			};

			mlb@0218c000 {
				compatible = "fsl,imx6q-mlb150";
				reg = <0x218c000 0x4000>;
				interrupts = <0x0 0x35 0x4 0x0 0x75 0x4 0x0 0x7e 0x4>;
				clocks = <0x2 0x8b 0x2 0xaf>;
				clock-names = "mlb", "pll8_mlb";
				iram = <0x13>;
				status = "disabled";
			};

			usdhc@02190000 {
				compatible = "fsl,imx6q-usdhc";
				reg = <0x2190000 0x4000>;
				interrupts = <0x0 0x16 0x4>;
				clocks = <0x2 0xa3 0x2 0xa3 0x2 0xa3>;
				clock-names = "ipg", "ahb", "per";
				bus-width = <0x4>;
				status = "okay";
				#address-cells = <0x1>;
				#size-cells = <0x0>;
				pinctrl-names = "default";
				pinctrl-0 = <0x30>;
				non-removable;
				no-1-8-v;
				keep-power-in-suspend;
				mmc-pwrseq = <0x31>;
				vmmc-supply = <0x32>;

				wifi@1 {
					compatible = "brcm,bcm4329-fmac";
					reg = <0x1>;
					pinctrl-names = "default";
					pinctrl-0 = <0x33>;
				};
			};

			usdhc@02194000 {
				compatible = "fsl,imx6q-usdhc";
				reg = <0x2194000 0x4000>;
				interrupts = <0x0 0x17 0x4>;
				clocks = <0x2 0xa4 0x2 0xa4 0x2 0xa4>;
				clock-names = "ipg", "ahb", "per";
				bus-width = <0x4>;
				status = "okay";
				pinctrl-names = "default", "state_100mhz", "state_200mhz";
				pinctrl-0 = <0x34 0x35>;
				pinctrl-1 = <0x34 0x36>;
				pinctrl-2 = <0x34 0x37>;
				vmmc-supply = <0x38>;
				cd-gpios = <0x39 0x4 0x1>;
			};

			usdhc@02198000 {
				compatible = "fsl,imx6q-usdhc";
				reg = <0x2198000 0x4000>;
				interrupts = <0x0 0x18 0x4>;
				clocks = <0x2 0xa5 0x2 0xa5 0x2 0xa5>;
				clock-names = "ipg", "ahb", "per";
				bus-width = <0x8>;
				status = "okay";
				pinctrl-names = "default";
				pinctrl-0 = <0x3a>;
				vmmc-supply = <0x3b>;
				vqmmc-supply = <0x3b>;
				non-removable;
			};

			usdhc@0219c000 {
				compatible = "fsl,imx6q-usdhc";
				reg = <0x219c000 0x4000>;
				interrupts = <0x0 0x19 0x4>;
				clocks = <0x2 0xa6 0x2 0xa6 0x2 0xa6>;
				clock-names = "ipg", "ahb", "per";
				bus-width = <0x4>;
				status = "disabled";
			};

			i2c@021a0000 {
				#address-cells = <0x1>;
				#size-cells = <0x0>;
				compatible = "fsl,imx6q-i2c", "fsl,imx21-i2c";
				reg = <0x21a0000 0x4000>;
				interrupts = <0x0 0x24 0x4>;
				clocks = <0x2 0x7d>;
				status = "okay";
				clock-frequency = <0x186a0>;
				pinctrl-names = "default";
				pinctrl-0 = <0x3c>;

				rtc@68 {
					compatible = "nxp,pcf8523";
					reg = <0x68>;
					nxp,12p5_pf;
				};

				codec@0a {
					clocks = <0x2 0xc9>;
					compatible = "fsl,sgtl5000";
					pinctrl-names = "default";
					pinctrl-0 = <0x3d>;
					reg = <0xa>;
					VDDA-supply = <0x3b>;
					VDDD-supply = <0x3e>;
					VDDIO-supply = <0x3b>;
					linux,phandle = <0x73>;
					phandle = <0x73>;
				};

				camera@3c {
					compatible = "ovti,ov5640_mipi";
					reg = <0x3c>;
					clocks = <0x2 0xc8>;
					clock-names = "csi_mclk";
					pwn-gpios = <0x2f 0xe 0x1>;
					rst-gpios = <0xf 0xa 0x0>;
					ipu_id = <0x0>;
					csi_id = <0x1>;
					mclk = <0x16e3600>;
					mclk_source = <0x0>;
					pinctrl-names = "default";
					pinctrl-0 = <0x3f>;
					extended-buffer;
				};
			};

			i2c@021a4000 {
				#address-cells = <0x1>;
				#size-cells = <0x0>;
				compatible = "fsl,imx6q-i2c", "fsl,imx21-i2c";
				reg = <0x21a4000 0x4000>;
				interrupts = <0x0 0x25 0x4>;
				clocks = <0x2 0x7e>;
				status = "okay";
				clock-frequency = <0x186a0>;
				pinctrl-names = "default";
				pinctrl-0 = <0x40>;
				linux,phandle = <0x6>;
				phandle = <0x6>;

				ddc@50 {
					compatible = "fsl,imx6-hdmi-i2c";
					reg = <0x50>;
				};
			};

			i2c@021a8000 {
				#address-cells = <0x1>;
				#size-cells = <0x0>;
				compatible = "fsl,imx6q-i2c", "fsl,imx21-i2c";
				reg = <0x21a8000 0x4000>;
				interrupts = <0x0 0x26 0x4>;
				clocks = <0x2 0x7f>;
				status = "okay";
				clock-frequency = <0x186a0>;
				pinctrl-names = "default";
				pinctrl-0 = <0x41>;
			};

			romcp@021ac000 {
				reg = <0x21ac000 0x4000>;
			};

			mmdc0-1@021b0000 {
				compatible = "fsl,imx6q-mmdc-combine";
				reg = <0x21b0000 0x8000>;
			};

			mmdc@021b0000 {
				compatible = "fsl,imx6q-mmdc";
				reg = <0x21b0000 0x4000>;
			};

			mmdc@021b4000 {
				reg = <0x21b4000 0x4000>;
			};

			weim@021b8000 {
				compatible = "fsl,imx6q-weim";
				reg = <0x21b8000 0x4000>;
				interrupts = <0x0 0xe 0x4>;
				clocks = <0x2 0xc4>;
			};

			ocotp@021bc000 {
				compatible = "fsl,imx6q-ocotp", "syscon";
				reg = <0x21bc000 0x4000>;
				clocks = <0x2 0x80>;
				linux,phandle = <0x19>;
				phandle = <0x19>;
			};

			tzasc@021d0000 {
				reg = <0x21d0000 0x4000>;
				interrupts = <0x0 0x6c 0x4>;
			};

			tzasc@021d4000 {
				reg = <0x21d4000 0x4000>;
				interrupts = <0x0 0x6d 0x4>;
			};

			audmux@021d8000 {
				compatible = "fsl,imx6q-audmux", "fsl,imx31-audmux";
				reg = <0x21d8000 0x4000>;
				status = "okay";
			};

			mipi_csi@021dc000 {
				compatible = "fsl,imx6q-mipi-csi2";
				reg = <0x21dc000 0x4000>;
				interrupts = <0x0 0x64 0x4 0x0 0x65 0x4>;
				clocks = <0x2 0x8a 0x2 0x35 0x2 0xee>;
				clock-names = "dphy_clk", "pixel_clk", "cfg_clk";
				status = "okay";
				ipu_id = <0x0>;
				csi_id = <0x1>;
				v_channel = <0x0>;
				lanes = <0x2>;
				mipi_dphy_clk = <0x14>;
			};

			mipi@021e0000 {
				reg = <0x21e0000 0x4000>;
				status = "disabled";
				compatible = "fsl,imx6q-mipi-dsi";
				interrupts = <0x0 0x66 0x4>;
				gpr = <0x4>;
				clocks = <0x2 0x8a 0x2 0xee>;
				clock-names = "mipi_pllref_clk", "mipi_cfg_clk";

				ports {
					#address-cells = <0x1>;
					#size-cells = <0x0>;

					port@0 {
						reg = <0x0>;

						endpoint {
							remote-endpoint = <0x42>;
							linux,phandle = <0x4c>;
							phandle = <0x4c>;
						};
					};

					port@1 {
						reg = <0x1>;

						endpoint {
							remote-endpoint = <0x43>;
							linux,phandle = <0x50>;
							phandle = <0x50>;
						};
					};

					port@2 {
						reg = <0x2>;

						endpoint {
							remote-endpoint = <0x44>;
							linux,phandle = <0x54>;
							phandle = <0x54>;
						};
					};

					port@3 {
						reg = <0x3>;

						endpoint {
							remote-endpoint = <0x45>;
							linux,phandle = <0x58>;
							phandle = <0x58>;
						};
					};
				};
			};

			vdoa@021e4000 {
				compatible = "fsl,imx6q-vdoa";
				reg = <0x21e4000 0x4000>;
				interrupts = <0x0 0x12 0x4>;
				clocks = <0x2 0xca>;
				iram = <0x13>;
			};

			serial@021e8000 {
				compatible = "fsl,imx6q-uart", "fsl,imx21-uart";
				reg = <0x21e8000 0x4000>;
				interrupts = <0x0 0x1b 0x4>;
				clocks = <0x2 0xa0 0x2 0xa1>;
				clock-names = "ipg", "per";
				dmas = <0x10 0x1b 0x4 0x0 0x10 0x1c 0x4 0x0>;
				dma-names = "rx", "tx";
				status = "disabled";
			};

			serial@021ec000 {
				compatible = "fsl,imx6q-uart", "fsl,imx21-uart";
				reg = <0x21ec000 0x4000>;
				interrupts = <0x0 0x1c 0x4>;
				clocks = <0x2 0xa0 0x2 0xa1>;
				clock-names = "ipg", "per";
				dmas = <0x10 0x1d 0x4 0x0 0x10 0x1e 0x4 0x0>;
				dma-names = "rx", "tx";
				status = "okay";
				pinctrl-names = "default";
				pinctrl-0 = <0x46>;
			};

			serial@021f0000 {
				compatible = "fsl,imx6q-uart", "fsl,imx21-uart";
				reg = <0x21f0000 0x4000>;
				interrupts = <0x0 0x1d 0x4>;
				clocks = <0x2 0xa0 0x2 0xa1>;
				clock-names = "ipg", "per";
				dmas = <0x10 0x1f 0x4 0x0 0x10 0x20 0x4 0x0>;
				dma-names = "rx", "tx";
				status = "okay";
				pinctrl-names = "default";
				pinctrl-0 = <0x47>;
				uart-has-rtscts;

				bluetooth {
					compatible = "brcm,bcm43438-bt";
					clocks = <0x48>;
					clock-names = "ext_clock";
					device-wakeup-gpios = <0x49 0x1 0x0>;
					shutdown-gpios = <0x49 0x5 0x0>;
					pinctrl-names = "default";
					pinctrl-0 = <0x4a>;
					max-speed = <0x2dc6c0>;
				};
			};

			serial@021f4000 {
				compatible = "fsl,imx6q-uart", "fsl,imx21-uart";
				reg = <0x21f4000 0x4000>;
				interrupts = <0x0 0x1e 0x4>;
				clocks = <0x2 0xa0 0x2 0xa1>;
				clock-names = "ipg", "per";
				dmas = <0x10 0x21 0x4 0x0 0x10 0x22 0x4 0x0>;
				dma-names = "rx", "tx";
				status = "disabled";
			};
		};

		ipu@02400000 {
			#address-cells = <0x1>;
			#size-cells = <0x0>;
			compatible = "fsl,imx6q-ipu";
			reg = <0x2400000 0x400000>;
			interrupts = <0x0 0x6 0x4 0x0 0x5 0x4>;
			clocks = <0x2 0x82 0x2 0x83 0x2 0x84 0x2 0x27 0x2 0x28 0x2 0x87 0x2 0x88 0x2 0x8 0x2 0xc3>;
			clock-names = "bus", "di0", "di1", "di0_sel", "di1_sel", "ldb_di0", "ldb_di1", "540m", "video_pll";
			resets = <0xb 0x2>;
			bypass_reset = <0x0>;

			port@0 {
				reg = <0x0>;
			};

			port@1 {
				reg = <0x1>;
			};

			port@2 {
				#address-cells = <0x1>;
				#size-cells = <0x0>;
				reg = <0x2>;
				linux,phandle = <0x5e>;
				phandle = <0x5e>;

				disp0-endpoint {
				};

				hdmi-endpoint {
					remote-endpoint = <0x4b>;
					linux,phandle = <0x7>;
					phandle = <0x7>;
				};

				mipi-endpoint {
					remote-endpoint = <0x4c>;
					linux,phandle = <0x42>;
					phandle = <0x42>;
				};

				lvds0-endpoint {
					remote-endpoint = <0x4d>;
					linux,phandle = <0x1e>;
					phandle = <0x1e>;
				};

				lvds1-endpoint {
					remote-endpoint = <0x4e>;
					linux,phandle = <0x22>;
					phandle = <0x22>;
				};
			};

			port@3 {
				#address-cells = <0x1>;
				#size-cells = <0x0>;
				reg = <0x3>;
				linux,phandle = <0x5f>;
				phandle = <0x5f>;

				disp1-endpoint {
				};

				hdmi-endpoint {
					remote-endpoint = <0x4f>;
					linux,phandle = <0x8>;
					phandle = <0x8>;
				};

				mipi-endpoint {
					remote-endpoint = <0x50>;
					linux,phandle = <0x43>;
					phandle = <0x43>;
				};

				lvds0-endpoint {
					remote-endpoint = <0x51>;
					linux,phandle = <0x1f>;
					phandle = <0x1f>;
				};

				lvds1-endpoint {
					remote-endpoint = <0x52>;
					linux,phandle = <0x23>;
					phandle = <0x23>;
				};
			};
		};

		busfreq {
			compatible = "fsl,imx_busfreq";
			clocks = <0x2 0xab 0x2 0x6 0x2 0xb 0x2 0x68 0x2 0xac 0x2 0x3a 0x2 0x12 0x2 0x3c 0x2 0x14 0x2 0x3>;
			clock-names = "pll2_bus", "pll2_pfd2_396m", "pll2_198m", "arm", "pll3_usb_otg", "periph", "periph_pre", "periph_clk2", "periph_clk2_sel", "osc";
			interrupts = <0x0 0x6b 0x4 0x0 0x70 0x4 0x0 0x71 0x4 0x0 0x72 0x4>;
			interrupt-names = "irq_busfreq_0", "irq_busfreq_1", "irq_busfreq_2", "irq_busfreq_3";
			fsl,max_ddr_freq = <0x1f78a400>;
		};

		sram@00905000 {
			compatible = "mmio-sram";
			reg = <0x905000 0x3b000>;
			clocks = <0x2 0x8e>;
			linux,phandle = <0x13>;
			phandle = <0x13>;
		};

		sata@02200000 {
			compatible = "fsl,imx6q-ahci";
			reg = <0x2200000 0x4000>;
			interrupts = <0x0 0x27 0x4>;
			clocks = <0x2 0x9a 0x2 0xbb 0x2 0x69>;
			clock-names = "sata", "sata_ref", "ahb";
			status = "okay";
			fsl,transmit-level-mV = <0x450>;
			fsl,transmit-boost-mdB = <0x0>;
			fsl,transmit-atten-16ths = <0x9>;
			fsl,no-spread-spectrum;
		};

		gpu@02204000 {
			compatible = "vivante,gc";
			reg = <0x2204000 0x4000>;
			interrupts = <0x0 0xb 0x4>;
			clocks = <0x2 0x8f 0x2 0x79>;
			clock-names = "bus", "core";
			power-domains = <0x1 0x1>;
			linux,phandle = <0x64>;
			phandle = <0x64>;
		};

		ipu@02800000 {
			#address-cells = <0x1>;
			#size-cells = <0x0>;
			compatible = "fsl,imx6q-ipu";
			reg = <0x2800000 0x400000>;
			interrupts = <0x0 0x8 0x4 0x0 0x7 0x4>;
			clocks = <0x2 0x85 0x2 0x86 0x2 0x89 0x2 0x29 0x2 0x2a 0x2 0x87 0x2 0x88 0x2 0x8 0x2 0xc3>;
			clock-names = "bus", "di0", "di1", "di0_sel", "di1_sel", "ldb_di0", "ldb_di1", "540m", "video_pll";
			resets = <0xb 0x4>;
			bypass_reset = <0x0>;

			port@0 {
				reg = <0x0>;
			};

			port@1 {
				reg = <0x1>;
			};

			port@2 {
				#address-cells = <0x1>;
				#size-cells = <0x0>;
				reg = <0x2>;
				linux,phandle = <0x60>;
				phandle = <0x60>;

				disp0-endpoint {
				};

				hdmi-endpoint {
					remote-endpoint = <0x53>;
					linux,phandle = <0x9>;
					phandle = <0x9>;
				};

				mipi-endpoint {
					remote-endpoint = <0x54>;
					linux,phandle = <0x44>;
					phandle = <0x44>;
				};

				lvds0-endpoint {
					remote-endpoint = <0x55>;
					linux,phandle = <0x20>;
					phandle = <0x20>;
				};

				lvds1-endpoint {
					remote-endpoint = <0x56>;
					linux,phandle = <0x24>;
					phandle = <0x24>;
				};
			};

			port@3 {
				#address-cells = <0x1>;
				#size-cells = <0x0>;
				reg = <0x3>;
				linux,phandle = <0x61>;
				phandle = <0x61>;

				hdmi-endpoint {
					remote-endpoint = <0x57>;
					linux,phandle = <0xa>;
					phandle = <0xa>;
				};

				mipi-endpoint {
					remote-endpoint = <0x58>;
					linux,phandle = <0x45>;
					phandle = <0x45>;
				};

				lvds0-endpoint {
					remote-endpoint = <0x59>;
					linux,phandle = <0x21>;
					phandle = <0x21>;
				};

				lvds1-endpoint {
					remote-endpoint = <0x5a>;
					linux,phandle = <0x25>;
					phandle = <0x25>;
				};
			};
		};
	};

	cpus {
		#address-cells = <0x1>;
		#size-cells = <0x0>;

		cpu@0 {
			compatible = "arm,cortex-a9";
			device_type = "cpu";
			reg = <0x0>;
			next-level-cache = <0x5b>;
			operating-points = <0x124f80 0x137478 0xf32a0 0x1312d0 0xd0020 0x1312d0 0xc15c0 0x11edd8 0x60ae0 0xee098>;
			fsl,soc-operating-points = <0x124f80 0x137478 0xf32a0 0x1312d0 0xd0020 0x1312d0 0xc15c0 0x11edd8 0x60ae0 0x11edd8>;
			clock-latency = <0xee6c>;
			clocks = <0x2 0x68 0x2 0x6 0x2 0x10 0x2 0x11 0x2 0xaa 0x2 0xdf 0x2 0xe6 0x2 0xd8 0x2 0x63>;
			clock-names = "arm", "pll2_pfd2_396m", "step", "pll1_sw", "pll1_sys", "pll1", "pll1_bypass", "pll1_bypass_src", "vpu_axi_podf";
			arm-supply = <0x5c>;
			pu-supply = <0x1c>;
			soc-supply = <0x5d>;
		};

		cpu@1 {
			compatible = "arm,cortex-a9";
			device_type = "cpu";
			reg = <0x1>;
			next-level-cache = <0x5b>;
		};

		cpu@2 {
			compatible = "arm,cortex-a9";
			device_type = "cpu";
			reg = <0x2>;
			next-level-cache = <0x5b>;
		};

		cpu@3 {
			compatible = "arm,cortex-a9";
			device_type = "cpu";
			reg = <0x3>;
			next-level-cache = <0x5b>;
		};
	};

	psci {
		compatible = "arm,psci-0.2";
		method = "smc";
	};

	reserved-memory {
		#address-cells = <0x1>;
		#size-cells = <0x1>;
		ranges;

		linux,cma {
			compatible = "shared-dma-pool";
			reusable;
			size = <0x2000000>;
			linux,cma-default;
			alloc-ranges = <0x0 0x40000000>;
			alignment = <0x400000>;
		};

		linux,gpu {
			compatible = "shared-dma-pool";
			reusable;
			size = <0x10000000>;
			alloc-ranges = <0x0 0x80000000>;
			alignment = <0x400000>;
			linux,phandle = <0xc>;
			phandle = <0xc>;
		};
	};

	display-subsystem {
		compatible = "fsl,imx-display-subsystem";
		ports = <0x5e 0x5f 0x60 0x61>;
	};

	gpu-subsystem {
		compatible = "fsl,imx-gpu-subsystem";
		cores = <0x62 0x63 0x64>;
	};

	regulator-vcc-3v3 {
		compatible = "regulator-fixed";
		regulator-always-on;
		regulator-name = "vcc_3v3";
		regulator-min-microvolt = <0x325aa0>;
		regulator-max-microvolt = <0x325aa0>;
		vin-supply = <0x3b>;
	};

	brcm-wifi-clock {
		compatible = "gpio-gate-clock";
		#clock-cells = <0x0>;
		clock-frequency = <0x8000>;
		pinctrl-names = "default";
		pinctrl-0 = <0x65>;
		enable-gpios = <0x66 0x5 0x0>;
		linux,phandle = <0x48>;
		phandle = <0x48>;
	};

	brcm-wifi-pwrseq {
		compatible = "mmc-pwrseq-simple";
		pinctrl-names = "default";
		pinctrl-0 = <0x67 0x68>;
		reset-gpios = <0x66 0x1a 0x1 0x49 0x0 0x1>;
		clocks = <0x48>;
		clock-names = "ext_clock";
		linux,phandle = <0x31>;
		phandle = <0x31>;
	};

	brcm-reg {
		compatible = "regulator-fixed";
		enable-active-high;
		gpio = <0x69 0x13 0x0>;
		pinctrl-names = "default";
		pinctrl-0 = <0x6a>;
		regulator-name = "brcm_reg";
		regulator-min-microvolt = <0x325aa0>;
		regulator-max-microvolt = <0x325aa0>;
		startup-delay-us = <0x30d40>;
		linux,phandle = <0x32>;
		phandle = <0x32>;
	};

	chosen {
		stdout-path = "/soc/aips-bus@02000000/spba-bus@02000000/serial@02020000";
		bootargs = "quiet console=ttymxc0,115200 root=/dev/mmcblk0p2 rw";
	};

	ir-receiver {
		compatible = "gpio-ir-receiver";
		gpios = <0x6b 0x9 0x1>;
		pinctrl-names = "default";
		pinctrl-0 = <0x6c>;
		linux,rc-map-name = "rc-rc6-mce";
	};

	regulator-v-3v2 {
		compatible = "regulator-fixed";
		regulator-always-on;
		regulator-max-microvolt = <0x325aa0>;
		regulator-min-microvolt = <0x325aa0>;
		regulator-name = "v_3v2";
		linux,phandle = <0x3b>;
		phandle = <0x3b>;
	};

	regulator-v-5v0 {
		compatible = "regulator-fixed";
		regulator-always-on;
		regulator-max-microvolt = <0x4c4b40>;
		regulator-min-microvolt = <0x4c4b40>;
		regulator-name = "v_5v0";
		linux,phandle = <0x6f>;
		phandle = <0x6f>;
	};

	regulator-vcc-1p8 {
		compatible = "regulator-fixed";
		regulator-always-on;
		regulator-max-microvolt = <0x1b7740>;
		regulator-min-microvolt = <0x1b7740>;
		regulator-name = "vcc_1p8";
		vin-supply = <0x3b>;
		linux,phandle = <0x3e>;
		phandle = <0x3e>;
	};

	regulator-v-sd {
		compatible = "regulator-fixed";
		gpio = <0x2f 0x1e 0x0>;
		pinctrl-names = "default";
		pinctrl-0 = <0x6d>;
		regulator-boot-on;
		regulator-max-microvolt = <0x325aa0>;
		regulator-min-microvolt = <0x325aa0>;
		regulator-name = "v_sd";
		startup-delay-us = <0x3e8>;
		vin-supply = <0x3b>;
		linux,phandle = <0x38>;
		phandle = <0x38>;
	};

	regulator-v-usb1 {
		compatible = "regulator-fixed";
		enable-active-high;
		gpio = <0x69 0x16 0x0>;
		pinctrl-names = "default";
		pinctrl-0 = <0x6e>;
		regulator-always-on;
		regulator-max-microvolt = <0x4c4b40>;
		regulator-min-microvolt = <0x4c4b40>;
		regulator-name = "v_usb1";
		vin-supply = <0x6f>;
		linux,phandle = <0x2a>;
		phandle = <0x2a>;
	};

	regulator-v-usb2 {
		compatible = "regulator-fixed";
		enable-active-high;
		gpio = <0x39 0x0 0x0>;
		pinctrl-names = "default";
		pinctrl-0 = <0x70>;
		regulator-always-on;
		regulator-max-microvolt = <0x4c4b40>;
		regulator-min-microvolt = <0x4c4b40>;
		regulator-name = "v_usb2";
		vin-supply = <0x6f>;
	};

	regulator-v-usb3 {
		compatible = "regulator-fixed";
		enable-active-high;
		gpio = <0xf 0xd 0x0>;
		pinctrl-names = "default";
		pinctrl-0 = <0x71>;
		regulator-always-on;
		regulator-max-microvolt = <0x4c4b40>;
		regulator-min-microvolt = <0x4c4b40>;
		regulator-name = "v_usb3";
		vin-supply = <0x6f>;
	};

	regulator-v-usb4 {
		compatible = "regulator-fixed";
		enable-active-high;
		gpio = <0x6b 0xa 0x0>;
		pinctrl-names = "default";
		pinctrl-0 = <0x72>;
		regulator-always-on;
		regulator-max-microvolt = <0x4c4b40>;
		regulator-min-microvolt = <0x4c4b40>;
		regulator-name = "v_usb4";
		vin-supply = <0x6f>;
	};

	sound-sgtl5000 {
		audio-codec = <0x73>;
		audio-routing = "MIC_IN", "Mic Jack", "Mic Jack", "Mic Bias", "Headphone Jack", "HP_OUT";
		compatible = "fsl,imx-audio-sgtl5000";
		model = "On-board Codec";
		mux-ext-port = <0x5>;
		mux-int-port = <0x1>;
		ssi-controller = <0x74>;
	};

	fb@0 {
		compatible = "fsl,mxc_sdc_fb";
		disp_dev = "hdmi";
		interface_pix_fmt = "RGB24";
		mode_str = "1920x1080M@60";
		default_bpp = <0x20>;
		int_clk = <0x0>;
		late_init = <0x0>;
		memory-region = <0xc>;
		status = "okay";
	};

	fb@1 {
		compatible = "fsl,mxc_sdc_fb";
		disp_dev = "ldb";
		interface_pix_fmt = "RGB666";
		default_bpp = <0x10>;
		int_clk = <0x0>;
		late_init = <0x0>;
		memory-region = <0xc>;
		status = "disabled";
	};

	sound-hdmi {
		compatible = "fsl,imx6q-audio-hdmi", "fsl,imx-audio-hdmi";
		model = "imx-audio-hdmi";
		hdmi-controller = <0x75>;
	};

	v4l2_cap_0 {
		compatible = "fsl,imx6q-v4l2-capture";
		ipu_id = <0x0>;
		csi_id = <0x1>;
		mclk_source = <0x0>;
		mipi_camera = <0x1>;
		default_input = <0x0>;
		status = "okay";
	};

	v4l2_out {
		compatible = "fsl,mxc_v4l2_output";
		status = "okay";
	};
};
